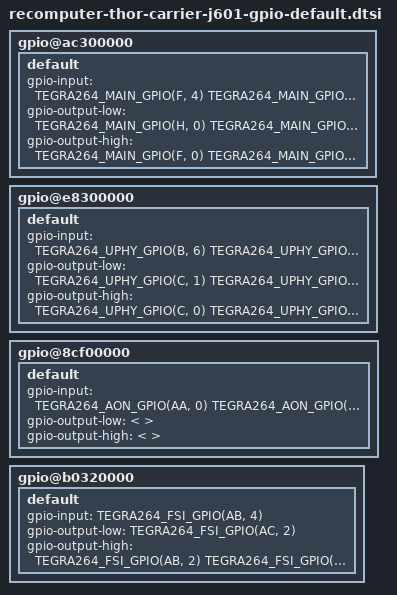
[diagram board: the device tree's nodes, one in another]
/*This dtsi file was generated by recomputer-thor-carrier-j601.xlsm Revision: 39 */
/*
 * SPDX-FileCopyrightText: Copyright (c) 2024 NVIDIA CORPORATION & AFFILIATES. All rights reserved.
 * SPDX-License-Identifier: BSD-3-Clause
 *
 * Redistribution and use in source and binary forms, with or without
 * modification, are permitted provided that the following conditions are met:
 *
 * 1. Redistributions of source code must retain the above copyright notice, this
 * list of conditions and the following disclaimer.
 *
 * 2. Redistributions in binary form must reproduce the above copyright notice,
 * this list of conditions and the following disclaimer in the documentation
 * and/or other materials provided with the distribution.
 * 
 * 3. Neither the name of the copyright holder nor the names of its
 * contributors may be used to endorse or promote products derived from
 * this software without specific prior written permission.
 *
 * THIS SOFTWARE IS PROVIDED BY THE COPYRIGHT HOLDERS AND CONTRIBUTORS 'AS IS'
 * AND ANY EXPRESS OR IMPLIED WARRANTIES, INCLUDING, BUT NOT LIMITED TO, THE
 * IMPLIED WARRANTIES OF MERCHANTABILITY AND FITNESS FOR A PARTICULAR PURPOSE ARE
 * DISCLAIMED. IN NO EVENT SHALL THE COPYRIGHT HOLDER OR CONTRIBUTORS BE LIABLE
 * FOR ANY DIRECT, INDIRECT, INCIDENTAL, SPECIAL, EXEMPLARY, OR CONSEQUENTIAL
 * DAMAGES (INCLUDING, BUT NOT LIMITED TO, PROCUREMENT OF SUBSTITUTE GOODS OR
 * SERVICES; LOSS OF USE, DATA, OR PROFITS; OR BUSINESS INTERRUPTION) HOWEVER
 * CAUSED AND ON ANY THEORY OF LIABILITY, WHETHER IN CONTRACT, STRICT LIABILITY,
 * OR TORT (INCLUDING NEGLIGENCE OR OTHERWISE) ARISING IN ANY WAY OUT OF THE USE
 * OF THIS SOFTWARE, EVEN IF ADVISED OF THE POSSIBILITY OF SUCH DAMAGE.
 */

#include "tegra264-gpio.h"

gpio@ac300000 {
	 default {
		gpio-input = <
			TEGRA264_MAIN_GPIO(F, 4)
			TEGRA264_MAIN_GPIO(H, 5)
			TEGRA264_MAIN_GPIO(H, 6)
			TEGRA264_MAIN_GPIO(H, 7)
			TEGRA264_MAIN_GPIO(J, 0)
			TEGRA264_MAIN_GPIO(J, 1)
			TEGRA264_MAIN_GPIO(J, 2)
			TEGRA264_MAIN_GPIO(L, 4)
			TEGRA264_MAIN_GPIO(M, 1)
			TEGRA264_MAIN_GPIO(P, 1)
			TEGRA264_MAIN_GPIO(Q, 4)
			TEGRA264_MAIN_GPIO(Q, 5)
			TEGRA264_MAIN_GPIO(Q, 6)
			TEGRA264_MAIN_GPIO(Q, 7)
			TEGRA264_MAIN_GPIO(S, 0)
			TEGRA264_MAIN_GPIO(S, 1)
			TEGRA264_MAIN_GPIO(T, 6)
			TEGRA264_MAIN_GPIO(U, 1)
			TEGRA264_MAIN_GPIO(U, 4)
			TEGRA264_MAIN_GPIO(U, 5)
			TEGRA264_MAIN_GPIO(V, 0)
			TEGRA264_MAIN_GPIO(V, 4)
			TEGRA264_MAIN_GPIO(Y, 2)
			TEGRA264_MAIN_GPIO(Y, 3)
			TEGRA264_MAIN_GPIO(Y, 4)
			TEGRA264_MAIN_GPIO(Y, 6)
			TEGRA264_MAIN_GPIO(Y, 7)
			TEGRA264_MAIN_GPIO(Z, 0)
			TEGRA264_MAIN_GPIO(Z, 1)
			TEGRA264_MAIN_GPIO(Z, 5)
			TEGRA264_MAIN_GPIO(Z, 6)
			TEGRA264_MAIN_GPIO(Z, 7)
			TEGRA264_MAIN_GPIO(AL, 0)
			>;
		gpio-output-low = <
			TEGRA264_MAIN_GPIO(H, 0)
			TEGRA264_MAIN_GPIO(H, 1)
			TEGRA264_MAIN_GPIO(L, 1)
			TEGRA264_MAIN_GPIO(P, 2)
			TEGRA264_MAIN_GPIO(P, 4)
			TEGRA264_MAIN_GPIO(P, 5)
			TEGRA264_MAIN_GPIO(Q, 2)
			TEGRA264_MAIN_GPIO(Q, 3)
			TEGRA264_MAIN_GPIO(R, 1)
			TEGRA264_MAIN_GPIO(U, 0)
			TEGRA264_MAIN_GPIO(U, 7)
			TEGRA264_MAIN_GPIO(V, 2)
			TEGRA264_MAIN_GPIO(V, 3)
			TEGRA264_MAIN_GPIO(AL, 1)
			TEGRA264_MAIN_GPIO(AL, 2)
			>;
		gpio-output-high = <
			TEGRA264_MAIN_GPIO(F, 0)
			TEGRA264_MAIN_GPIO(F, 1)
			TEGRA264_MAIN_GPIO(F, 2)
			TEGRA264_MAIN_GPIO(L, 3)
			TEGRA264_MAIN_GPIO(P, 0)
			TEGRA264_MAIN_GPIO(U, 3)
			TEGRA264_MAIN_GPIO(U, 6)
			TEGRA264_MAIN_GPIO(V, 5)
			TEGRA264_MAIN_GPIO(Y, 0)
			TEGRA264_MAIN_GPIO(Y, 1)
			TEGRA264_MAIN_GPIO(Y, 5)
			>;
	};
};
gpio@e8300000 {
	 default {
		gpio-input = <
			TEGRA264_UPHY_GPIO(B, 6)
			TEGRA264_UPHY_GPIO(B, 7)
			TEGRA264_UPHY_GPIO(C, 2)
			>;
		gpio-output-low = <
			TEGRA264_UPHY_GPIO(C, 1)
			TEGRA264_UPHY_GPIO(E, 1)
			>;
		gpio-output-high = <
			TEGRA264_UPHY_GPIO(C, 0)
			TEGRA264_UPHY_GPIO(E, 0)
			>;
	};
};
gpio@8cf00000 {
	 default {
		gpio-input = <
			TEGRA264_AON_GPIO(AA, 0)
			TEGRA264_AON_GPIO(AA, 4)
			TEGRA264_AON_GPIO(AA, 5)
			TEGRA264_AON_GPIO(AA, 7)
			TEGRA264_AON_GPIO(BB, 0)
			TEGRA264_AON_GPIO(BB, 1)
			TEGRA264_AON_GPIO(DD, 3)
			TEGRA264_AON_GPIO(DD, 4)
			TEGRA264_AON_GPIO(DD, 6)
			TEGRA264_AON_GPIO(EE, 1)
			>;
		gpio-output-low = <
			>;
		gpio-output-high = <
			>;
	};
};
gpio@b0320000 {
	 default {
		gpio-input = <
			TEGRA264_FSI_GPIO(AB, 4)
			>;
		gpio-output-low = <
			TEGRA264_FSI_GPIO(AC, 2)
			>;
		gpio-output-high = <
			TEGRA264_FSI_GPIO(AB, 2)
			TEGRA264_FSI_GPIO(AB, 3)
			>;
	};
};
